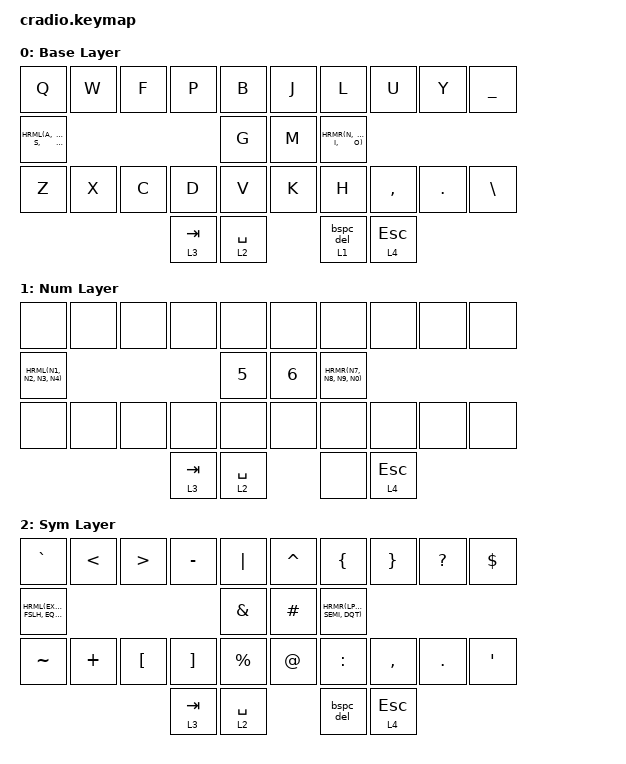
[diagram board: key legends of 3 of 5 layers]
// Copyright (c) 2022 The ZMK Contributors
// SPDX-License-Identifier: MIT

#include <behaviors.dtsi>
#include <dt-bindings/zmk/keys.h>
#include <dt-bindings/zmk/bt.h>
#include <dt-bindings/zmk/outputs.h>

// Home row mods macro
#define HRML(k1,k2,k3,k4) &ht LCTRL k1  &ht LSHFT k2  &ht LALT k3  &ht LGUI k4
#define HRMR(k1,k2,k3,k4) &ht RGUI k1  &ht RALT k2  &ht RSHFT k3  &ht RCTRL k4

/ {
    behaviors {
        ht: hold_tap {
            compatible = "zmk,behavior-hold-tap";
            #binding-cells = <2>;
            flavor = "balanced";
            tapping-term-ms = <220>;
            require-prior-idle-ms = <100>;
            bindings = <&kp>, <&kp>;
        };
        bspc_del: backspace_delete {
            compatible = "zmk,behavior-mod-morph";
            #binding-cells = <0>;
            bindings = <&kp BSPC>, <&kp DELETE>;
            mods = <(MOD_LSFT|MOD_RSFT)>;
        };
        lt_bspc_del: layer_tap_backspace_delete {
            compatible = "zmk,behavior-hold-tap";
            #binding-cells = <2>;
            flavor = "balanced";
            tapping-term-ms = <220>;
            bindings = <&mo>, <&bspc_del>;
	};
	tdh_llc: tap_dance_hold_left_lctrl {
            compatible = "zmk,behavior-tap-dance";
            #binding-cells = <0>;
            tapping-term-ms = <200>;
            bindings = <&ht LCTRL LEFT>, <&kp LEFT>;
        };
	tdh_dls: tap_dance_hold_down_lshft {
            compatible = "zmk,behavior-tap-dance";
            #binding-cells = <0>;
            tapping-term-ms = <250>;
            bindings = <&ht LSHFT DOWN>, <&kp DOWN>;
        };
	tdh_ula: tap_dance_hold_up_lalt {
            compatible = "zmk,behavior-tap-dance";
            #binding-cells = <0>;
            tapping-term-ms = <200>;
            bindings = <&ht LALT UP>, <&kp UP>;
        };
	tdh_rlg: tap_dance_hold_right_lgui {
            compatible = "zmk,behavior-tap-dance";
            #binding-cells = <0>;
            tapping-term-ms = <200>;
            bindings = <&ht LGUI RIGHT>, <&kp RIGHT>;
        };
        btldr_h: bootloader_hold {
            compatible = "zmk,behavior-hold-tap";
            #binding-cells = <2>;
            flavor = "balanced";
            tapping-term-ms = <500>;
            bindings = <&bootloader>, <&none>;
        };
    };

    combos {
        compatible = "zmk,combos";
        combo_enter_left {
            timeout-ms = <25>;
            key-positions = <11 12>;
            bindings = <&kp ENTER>;
        };
        compatible = "zmk,combos";
        combo_enter_right {
            timeout-ms = <25>;
            key-positions = <17 18>;
            bindings = <&kp ENTER>;
        };
        compatible = "zmk,combos";
        combo_caps_word {
            timeout-ms = <50>;
            key-positions = <11 18>;
            bindings = <&caps_word>;
        };
    };

    keymap {
        compatible = "zmk,keymap";
        base_layer {
            display-name = "Base Layer";
            bindings = <
             
            &kp Q      &kp W      &kp F      &kp P      &kp B          &kp J      &kp L      &kp U      &kp Y      &kp UNDERSCORE
       
            HRML(A,        R,         S,         T)     &kp G          &kp M      HRMR(N,        E,         I,        O)
        
           
            &kp Z      &kp X      &kp C      &kp D      &kp V          &kp K      &kp H      &kp COMMA  &kp DOT    &kp BACKSLASH
       
                                         &lt 3 TAB  &lt 2 SPACE        &lt_bspc_del 1 0  &lt 4 ESC
        
            >;
        };

        num_layer {
            display-name = "Num Layer";
            bindings = <
        
            &none &none &none &none &none   &none &none &none &none &none
       
              HRML(N1, N2, N3, N4) &kp N5   &kp N6 HRMR(N7, N8, N9, N0)
       
    	    &none &none &none &none &none   &none &none &none &none &none
        
                   &lt 3 TAB  &lt 2 SPACE   &none  &lt 4 ESC
            >;
        };

        sym_layer {
            display-name = "Sym Layer";
            bindings = <
        
    &kp GRAVE &kp LT &kp GT &kp MINUS &kp PIPE     &kp CARET &kp LBRC &kp RBRC &kp QUESTION &kp DOLLAR
    
        HRML(EXCL, STAR, FSLH, EQUAL) &kp AMPS     &kp HASH HRMR(LPAR, RPAR, SEMI, DQT)

&kp TILDE &kp PLUS &kp LBKT &kp RBKT &kp PRCNT     &kp AT &kp COLON &kp COMMA &kp DOT &kp SQT
                                     
	 				    &lt 3 TAB  &lt 2 SPACE     &bspc_del  &lt 4 ESC
            >;
        };

        util_layer {
            display-name = "Util Layer";
            bindings = <
        
&kp PSCRN &kp HOME &kp PG_UP &kp C_BRI_UP &kp C_VOL_UP     &kp C_NEXT &kp F1 &kp F2 &kp F3 &kp F4

        &tdh_llc &tdh_dls &tdh_ula &tdh_rlg &kp C_MUTE     &kp C_PP &ht RGUI F5 &ht RALT F6 &ht RSHFT F7 &ht RCTRL F8

     &none &kp END &kp PG_DN &kp C_BRI_DN &kp C_VOL_DN     &kp C_PREV &kp F9 &kp F10 &kp F11 &kp F12

    					        &lt 3 TAB  &lt 2 SPACE     &bspc_del  &lt 4 ESC
            >;
        };

prog_layer {
            display-name = "Prog Layer";
            bindings = <
        
        		     &btldr_h 0 0 &none &none &none &out OUT_USB     &bt BT_CLR &none &none &none &btldr_h 0 0
       
&bt BT_SEL 0 &bt BT_SEL 1 &bt BT_SEL 2 &bt BT_SEL 3 &bt BT_SEL 4     &bt BT_DISC 4 &bt BT_DISC 3 &bt BT_DISC 2 &bt BT_DISC 1 &bt BT_DISC 0
       
    	    		        &none &none &none &none &out OUT_BLE     &bt BT_CLR_ALL &none &none &none &none
        
                                          &lt 3 TAB  &lt 2 SPACE     &bspc_del  &lt 4 ESC
            >;
        };
    };
};
